VERSION ""

NS_ :

BS_:

BU_:

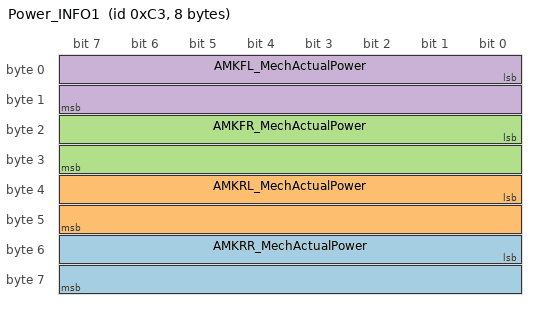
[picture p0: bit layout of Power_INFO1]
BO_ 195 Power_INFO1: 8 Vector__XXX
 SG_ AMKRR_MechActualPower : 48|16@1- (0.01,0) [-327.68|327.67] "kW" Vector__XXX
 SG_ AMKRL_MechActualPower : 32|16@1- (0.01,0) [-327.68|327.67] "kW" Vector__XXX
 SG_ AMKFR_MechActualPower : 16|16@1- (0.01,0) [-327.68|327.67] "kW" Vector__XXX
 SG_ AMKFL_MechActualPower : 0|16@1- (0.01,0) [-327.68|327.67] "kW" Vector__XXX

BA_DEF_  "BusType" STRING ;
BA_DEF_DEF_  "BusType" "CAN";
